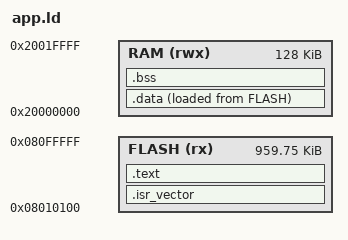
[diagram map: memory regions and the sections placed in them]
/* Application: lives behind the bootloader (64 KiB) and the 256-byte image header. */
ENTRY(Reset_Handler)
MEMORY
{
  FLASH (rx)  : ORIGIN = 0x08010100, LENGTH = 1024K - 64K - 256
  RAM   (rwx) : ORIGIN = 0x20000000, LENGTH = 128K
}
_estack = ORIGIN(RAM) + LENGTH(RAM);
SECTIONS
{
  .isr_vector : { KEEP(*(.isr_vector)) } > FLASH
  .text : { *(.text*) *(.rodata*) . = ALIGN(4); } > FLASH
  _sidata = LOADADDR(.data);
  .data : { _sdata = .; *(.data*) . = ALIGN(4); _edata = .; } > RAM AT > FLASH
  .bss  : { _sbss = .; *(.bss*) *(COMMON) . = ALIGN(4); _ebss = .; } > RAM
}
